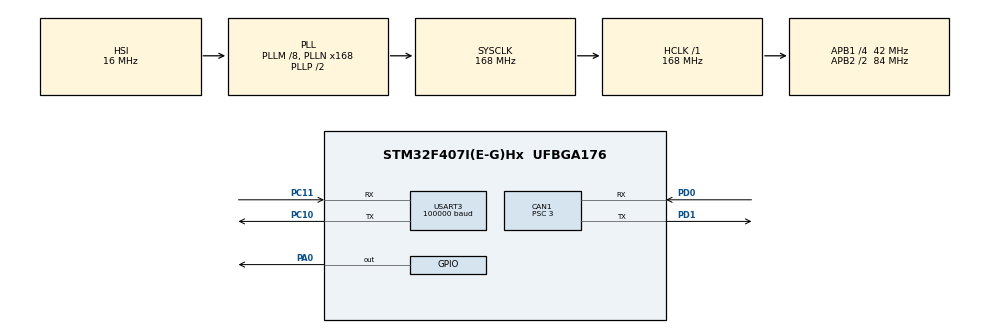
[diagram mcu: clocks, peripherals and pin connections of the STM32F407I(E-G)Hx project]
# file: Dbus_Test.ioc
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CAN1.BS1=CAN_BS1_10TQ
CAN1.BS2=CAN_BS2_3TQ
CAN1.CalculateBaudRate=1000000
CAN1.CalculateTimeBit=1000
CAN1.CalculateTimeQuantum=71.42857142857143
CAN1.Prescaler=3
Dma.Request0=USART3_RX
Dma.USART3_RX.0.Direction=DMA_PERIPH_TO_MEMORY
Dma.USART3_RX.0.FIFOMode=DMA_FIFOMODE_DISABLE
Dma.USART3_RX.0.Instance=DMA1_Stream1
Dma.USART3_RX.0.MemDataAlignment=DMA_MDATAALIGN_BYTE
Dma.USART3_RX.0.MemInc=DMA_MINC_ENABLE
Dma.USART3_RX.0.Mode=DMA_CIRCULAR
Dma.USART3_RX.0.PeriphDataAlignment=DMA_PDATAALIGN_BYTE
Dma.USART3_RX.0.PeriphInc=DMA_PINC_DISABLE
Dma.USART3_RX.0.Priority=DMA_PRIORITY_VERY_HIGH
Mcu.Family=STM32F4
Mcu.Name=STM32F407I(E-G)Hx
Mcu.Package=UFBGA176
NVIC.CAN1_RX0_IRQn=true\:0\:0\:false\:false\:true\:true\:true\:true
NVIC.DMA1_Stream1_IRQn=true\:0\:0\:false\:false\:true\:false\:true\:true
NVIC.PriorityGroup=NVIC_PRIORITYGROUP_4
NVIC.TIM3_IRQn=true\:0\:0\:false\:false\:true\:true\:true\:true
NVIC.USART3_IRQn=true\:0\:0\:false\:false\:true\:true\:true\:true
PA0-WKUP.GPIO_ModeDefaultOutputPP=GPIO_MODE_OUTPUT_PP
PA0-WKUP.GPIO_PuPd=GPIO_NOPULL
PA0-WKUP.Signal=GPIO_Output
PA13.Mode=Serial_Wire
PA13.Signal=SYS_JTMS-SWDIO
PA14.Mode=Serial_Wire
PA14.Signal=SYS_JTCK-SWCLK
PC10.Mode=Asynchronous
PC10.Signal=USART3_TX
PC11.Mode=Asynchronous
PC11.Signal=USART3_RX
PD0.Mode=CAN_Activate
PD0.Signal=CAN1_RX
PD1.Mode=CAN_Activate
PD1.Signal=CAN1_TX
ProjectManager.HeapSize=0x200
ProjectManager.StackSize=0x400
ProjectManager.TargetToolchain=MDK-ARM V5.32
RCC.48MHZClocksFreq_Value=84000000
RCC.AHBFreq_Value=168000000
RCC.APB1CLKDivider=RCC_HCLK_DIV4
RCC.APB1Freq_Value=42000000
RCC.APB1TimFreq_Value=84000000
RCC.APB2CLKDivider=RCC_HCLK_DIV2
RCC.APB2Freq_Value=84000000
RCC.APB2TimFreq_Value=168000000
RCC.CortexFreq_Value=168000000
RCC.HCLKFreq_Value=168000000
RCC.HSE_VALUE=25000000
RCC.HSI_VALUE=16000000
RCC.LSE_VALUE=32768
RCC.PLLM=8
RCC.PLLN=168
RCC.SYSCLKFreq_VALUE=168000000
RCC.SYSCLKSource=RCC_SYSCLKSOURCE_PLLCLK
RCC.VCOOutputFreq_Value=336000000
TIM3.Period=1000-1
TIM3.Prescaler=84-1
USART3.BaudRate=100000
USART3.Parity=PARITY_EVEN
USART3.VirtualMode=VM_ASYNC
USART3.WordLength=WORDLENGTH_9B
VP_TIM3_VS_ClockSourceINT.Mode=Internal
board=custom

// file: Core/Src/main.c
/* USER CODE BEGIN Header */
/**
 ******************************************************************************
 * @file           : main.c
 * @brief          : Main program body
 ******************************************************************************
 * @attention
 *
 * Copyright (c) 2024 STMicroelectronics.
 * All rights reserved.
 *
 * This software is licensed under terms that can be found in the LICENSE file
 * in the root directory of this software component.
 * If no LICENSE file comes with this software, it is provided AS-IS.
 *
 ******************************************************************************
 */
/* USER CODE END Header */
#include "main.h"
#include "can.h"
#include "dma.h"
#include "tim.h"
#include "usart.h"
#include "gpio.h"

/* USER CODE BEGIN Includes */
#include "can_config.h"
#include "remote_rc.h"
#include "pid.h"
/* USER CODE END Includes */

/* USER CODE BEGIN PV */
CAN_Feedback_t Can_Feedback[2];

/* USER CODE END PV */

void SystemClock_Config(void);

/* USER CODE BEGIN 0 */

void HAL_CAN_RxFifo0MsgPendingCallback(CAN_HandleTypeDef *hcan);

dataBuffer_t dataBuffer;

void HAL_UART_RxCpltCallback(UART_HandleTypeDef *UartHandle)
{
	DecodeData(rxBuffer,&dataBuffer);
}

/* USER CODE END 0 */

int main(void)
{

  /* MCU Configuration--------------------------------------------------------*/

  /* Reset of all peripherals, Initializes the Flash interface and the Systick. */
  HAL_Init();

  /* Configure the system clock */
  SystemClock_Config();

  /* Initialize all configured peripherals */
  MX_GPIO_Init();
  MX_DMA_Init();
  MX_USART3_UART_Init();
  MX_CAN1_Init();
  MX_TIM3_Init();
  /* USER CODE BEGIN 2 */
  //UART_InitDMAReceive();
	HAL_UART_Receive_DMA(&huart3, (uint8_t *)rxBuffer, rxBufferLen);
	can_filter_init();
	Pid_init();
	 HAL_TIM_Base_Start_IT(&htim3);
	HAL_Delay(200);
  /* USER CODE END 2 */

  /* Infinite loop */
  /* USER CODE BEGIN WHILE */
  while (1)
  {
/*
	PID_ERR=target_Speed[0]-Can_Feedback[0].Speed;
	Interal+=PID_ERR;
	PID_OUT = Kp * PID_ERR + Ki * Interal + Kd * (Can_Feedback[0].Speed-Can_Feedback[1].Last_speed);
	if(PID_OUT>=25000){
		PID_OUT=25000;
	}
	else if(PID_OUT<=-25000){
		PID_OUT = -25000;
	}
		*/

		/*
	CAN_ctrl(PID_OUT,dataBuffer.Channel_2 * MOTOR_RATIO);
		HAL_Delay(1);*/
    /* USER CODE END WHILE */

  }
}

void SystemClock_Config(void)
{
  RCC_OscInitTypeDef RCC_OscInitStruct = {0};
  RCC_ClkInitTypeDef RCC_ClkInitStruct = {0};

  /** Configure the main internal regulator output voltage
  */
  __HAL_RCC_PWR_CLK_ENABLE();
  __HAL_PWR_VOLTAGESCALING_CONFIG(PWR_REGULATOR_VOLTAGE_SCALE1);

  /** Initializes the RCC Oscillators according to the specified parameters
  * in the RCC_OscInitTypeDef structure.
  */
  RCC_OscInitStruct.OscillatorType = RCC_OSCILLATORTYPE_HSI;
  RCC_OscInitStruct.HSIState = RCC_HSI_ON;
  RCC_OscInitStruct.HSICalibrationValue = RCC_HSICALIBRATION_DEFAULT;
  RCC_OscInitStruct.PLL.PLLState = RCC_PLL_ON;
  RCC_OscInitStruct.PLL.PLLSource = RCC_PLLSOURCE_HSI;
  RCC_OscInitStruct.PLL.PLLM = 8;
  RCC_OscInitStruct.PLL.PLLN = 168;
  RCC_OscInitStruct.PLL.PLLP = RCC_PLLP_DIV2;
  RCC_OscInitStruct.PLL.PLLQ = 4;
  if (HAL_RCC_OscConfig(&RCC_OscInitStruct) != HAL_OK)
  {
    Error_Handler();
  }

  /** Initializes the CPU, AHB and APB buses clocks
  */
  RCC_ClkInitStruct.ClockType = RCC_CLOCKTYPE_HCLK|RCC_CLOCKTYPE_SYSCLK
                              |RCC_CLOCKTYPE_PCLK1|RCC_CLOCKTYPE_PCLK2;
  RCC_ClkInitStruct.SYSCLKSource = RCC_SYSCLKSOURCE_PLLCLK;
  RCC_ClkInitStruct.AHBCLKDivider = RCC_SYSCLK_DIV1;
  RCC_ClkInitStruct.APB1CLKDivider = RCC_HCLK_DIV4;
  RCC_ClkInitStruct.APB2CLKDivider = RCC_HCLK_DIV2;

  if (HAL_RCC_ClockConfig(&RCC_ClkInitStruct, FLASH_LATENCY_5) != HAL_OK)
  {
    Error_Handler();
  }
}

/* USER CODE BEGIN 4 */

/*
void HAL_CAN_RxFifo0MsgPendingCallback(CAN_HandleTypeDef *hcan)
{
	if(hcan==&hcan1)
	{
		CAN_RxHeaderTypeDef CAN_rx;
		uint8_t data_rx[8];
		HAL_CAN_GetRxMessage(&hcan1,CAN_RX_FIFO0,&CAN_rx,data_rx);
		if(CAN_rx.StdId==0x205)
		{
			for(int i=FilterLength-1;i>0;i--)
			{
				Can_Feedback[0].Last_speed[i]=Can_Feedback[0].Last_speed[i-1];
			}
			Can_Feedback[0].Mechnical_angle=((uint16_t) data_rx[0] <<8) | (uint16_t)data_rx[1];
			Can_Feedback[0].Speed=((uint16_t) data_rx[2] <<8) | (uint16_t)data_rx[3];
			Can_Feedback[0].Last_speed[0]=Can_Feedback[0].Speed;
			Can_Feedback[0].Torque_current=((uint16_t) data_rx[4] <<8) | (uint16_t)data_rx[5];
			Can_Feedback[0].Temprature=data_rx[6];
		}
		else if (CAN_rx.StdId==0x206)
		{
			Can_Feedback[1].Last_speed[0]=Can_Feedback[1].Speed;
			Can_Feedback[1].Mechnical_angle=((uint16_t) data_rx[0] <<8) | (uint16_t)data_rx[1];
			Can_Feedback[1].Speed=((uint16_t) data_rx[2] <<8) | (uint16_t)data_rx[3];
			Can_Feedback[1].Torque_current=((uint16_t) data_rx[4] <<8) | (uint16_t)data_rx[5];
			Can_Feedback[1].Temprature=data_rx[6];
		}
	}
	return;
}
*/

/*
void HAL_TIM_PeriodElapsedCallback(TIM_HandleTypeDef *htim)
{
	if(htim==&htim3)
	{
	target_Speed[0]= (float)dataBuffer.Channel_1/33*16;
	target_Speed[1]= (float)dataBuffer.Channel_2/33*16;
	target_Angle[0]= (float)dataBuffer.Channel_1*5+4096;
	uint16_t Current_Speed=0;

	for(int i=0;i<FilterLength-1;i++)  //filter
		{
			Current_Speed+=Can_Feedback[0].Last_speed[i]/FilterLength;
		}

	PID.ERR=target_Speed[0]-Current_Speed;
	Interal+=PID.ERR;
	PID.OUT = PID.Kp * (float)PID.ERR + PID.Ki * (float)Interal + PID.Kd * (PID.ERR-PID.Last_ERR);
	if(PID.OUT>=25000){
		PID.OUT=25000;
	}
	else if(PID.OUT<=-25000){
		PID.OUT = -25000;
	}
	PID.Last_ERR=PID.ERR;
	CAN_ctrl(PID.OUT,dataBuffer.Channel_2 * MOTOR_RATIO);
	}
}

*/

/* USER CODE END 4 */

void Error_Handler(void)
{
  __disable_irq();
  while (1)
  {
  }
}
